# ioam3358 register map
Registers are 32-bit, access not given, no defined reset value unless marked. A register's access mark holds for its fields unless they carry their own. Addresses are absolute; registers are grouped by the start of their names; [hi:lo] are bit positions; {n}, {i} and the like mark numbered series.

## MCSPI1
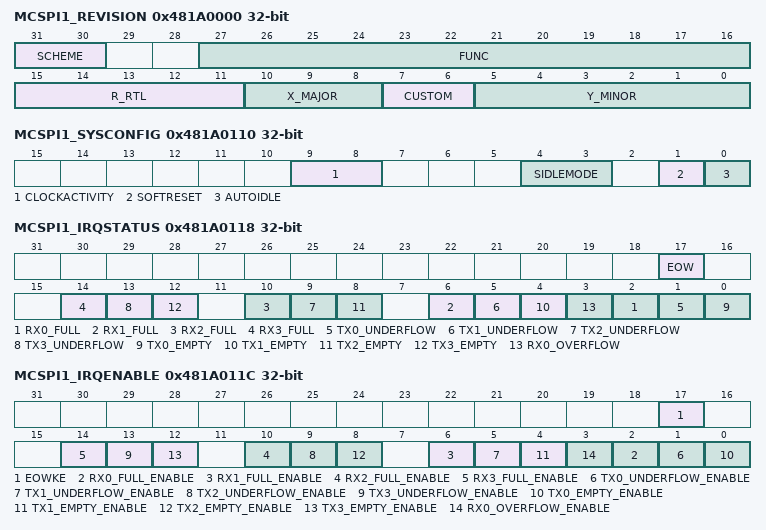
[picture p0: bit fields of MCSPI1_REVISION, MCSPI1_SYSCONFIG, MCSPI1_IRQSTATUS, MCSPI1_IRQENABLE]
0x481A0000 MCSPI1_REVISION
  [31:30] SCHEME, [27:16] FUNC, [15:11] R_RTL, [10:8] X_MAJOR, [7:6] CUSTOM, [5:0] Y_MINOR
0x481A0110 MCSPI1_SYSCONFIG
  [9:8] CLOCKACTIVITY, [4:3] SIDLEMODE, [1] SOFTRESET, [0] AUTOIDLE
0x481A0114 MCSPI1_SYSSTATUS
  [0] RESETDONE
0x481A0118 MCSPI1_IRQSTATUS
  [17] EOW, [4n+2] RX{n}_FULL (n=0..3), [4n+1] TX{n}_UNDERFLOW (n=0..3), [4n] TX{n}_EMPTY (n=0..3), [3] RX0_OVERFLOW
0x481A011C MCSPI1_IRQENABLE
  [17] EOWKE, [4n+2] RX{n}_FULL_ENABLE (n=0..3), [4n+1] TX{n}_UNDERFLOW_ENABLE (n=0..3), [4n] TX{n}_EMPTY_ENABLE (n=0..3), [3] RX0_OVERFLOW_ENABLE
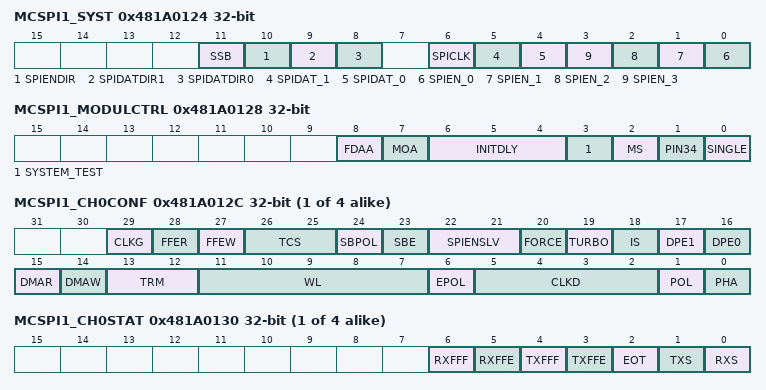
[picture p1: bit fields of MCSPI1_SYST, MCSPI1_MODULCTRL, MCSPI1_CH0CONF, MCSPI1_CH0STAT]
0x481A0124 MCSPI1_SYST
  [11] SSB, [10] SPIENDIR, [9] SPIDATDIR1, [8] SPIDATDIR0, [6] SPICLK, [5] SPIDAT_1, [4] SPIDAT_0, [n] SPIEN_{n} (n=0..3)
0x481A0128 MCSPI1_MODULCTRL
  [8] FDAA, [7] MOA, [6:4] INITDLY, [3] SYSTEM_TEST, [2] MS, [1] PIN34, [0] SINGLE
{0x481A012C+0x14*i} MCSPI1_CH{i}CONF (i=0..3)
  [29] CLKG, [28] FFER, [27] FFEW, [26:25] TCS, [24] SBPOL, [23] SBE, [22:21] SPIENSLV, [20] FORCE, [19] TURBO, [18] IS, [17] DPE1, [16] DPE0, [15] DMAR, [14] DMAW, [13:12] TRM, [11:7] WL, [6] EPOL, [5:2] CLKD, [1] POL, [0] PHA
{0x481A0130+0x14*i} MCSPI1_CH{i}STAT (i=0..3)
  [6] RXFFF, [5] RXFFE, [4] TXFFF, [3] TXFFE, [2] EOT, [1] TXS, [0] RXS
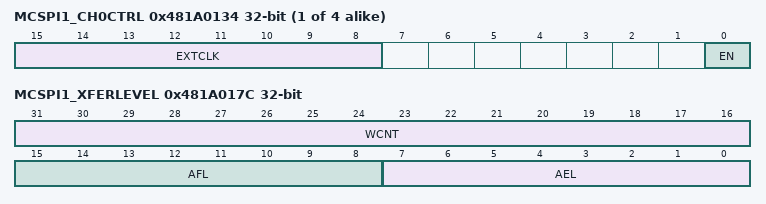
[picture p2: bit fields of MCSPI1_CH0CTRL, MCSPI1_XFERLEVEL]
{0x481A0134+0x14*i} MCSPI1_CH{i}CTRL (i=0..3)
  [15:8] EXTCLK, [0] EN
{0x481A0138+0x14*i} MCSPI1_TX{i} (i=0..3)
{0x481A013C+0x14*i} MCSPI1_RX{i} (i=0..3)
0x481A017C MCSPI1_XFERLEVEL
  [31:16] WCNT, [15:8] AFL, [7:0] AEL
0x481A0180 MCSPI1_DAFTX
0x481A0184 MCSPI1_DAFRX

## GPIO0
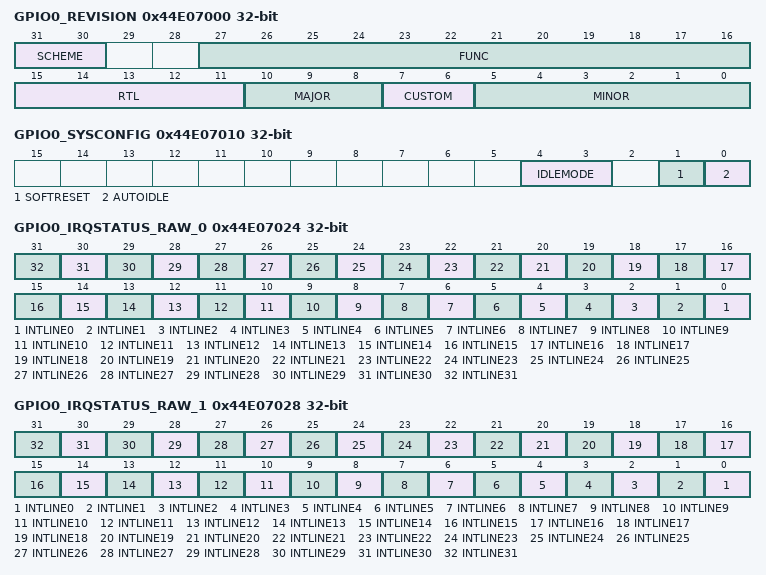
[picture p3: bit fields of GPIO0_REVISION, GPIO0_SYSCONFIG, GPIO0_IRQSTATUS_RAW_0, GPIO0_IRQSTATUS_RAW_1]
0x44E07000 GPIO0_REVISION
  [31:30] SCHEME, [27:16] FUNC, [15:11] RTL, [10:8] MAJOR, [7:6] CUSTOM, [5:0] MINOR
0x44E07010 GPIO0_SYSCONFIG
  [4:3] IDLEMODE, [1] SOFTRESET, [0] AUTOIDLE
0x44E07020 GPIO0_GPIO_EOI
  [0] LINE_NUMBER
0x44E07024 GPIO0_IRQSTATUS_RAW_0
  [n] INTLINE{n} (n=0..31)
0x44E07028 GPIO0_IRQSTATUS_RAW_1
  [n] INTLINE{n} (n=0..31)
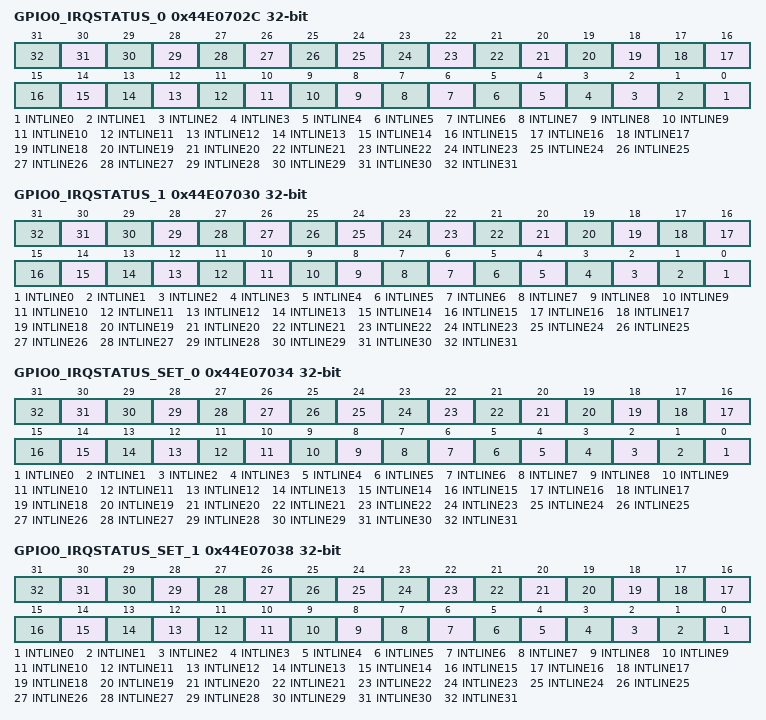
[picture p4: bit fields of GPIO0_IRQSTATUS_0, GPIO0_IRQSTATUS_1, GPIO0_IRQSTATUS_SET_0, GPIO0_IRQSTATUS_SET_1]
0x44E0702C GPIO0_IRQSTATUS_0
  [n] INTLINE{n} (n=0..31)
0x44E07030 GPIO0_IRQSTATUS_1
  [n] INTLINE{n} (n=0..31)
0x44E07034 GPIO0_IRQSTATUS_SET_0
  [n] INTLINE{n} (n=0..31)
0x44E07038 GPIO0_IRQSTATUS_SET_1
  [n] INTLINE{n} (n=0..31)
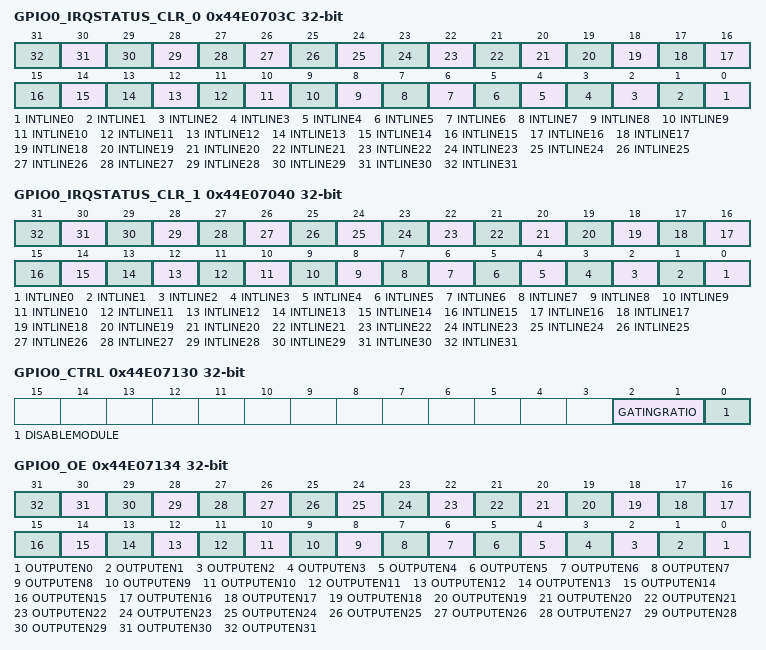
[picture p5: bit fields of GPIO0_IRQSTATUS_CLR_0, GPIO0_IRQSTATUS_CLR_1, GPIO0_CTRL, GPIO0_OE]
0x44E0703C GPIO0_IRQSTATUS_CLR_0
  [n] INTLINE{n} (n=0..31)
0x44E07040 GPIO0_IRQSTATUS_CLR_1
  [n] INTLINE{n} (n=0..31)
0x44E07114 GPIO0_SYSSTATUS
  [0] RESETDONE
0x44E07130 GPIO0_CTRL
  [2:1] GATINGRATIO, [0] DISABLEMODULE
0x44E07134 GPIO0_OE
  [n] OUTPUTEN{n} (n=0..31)
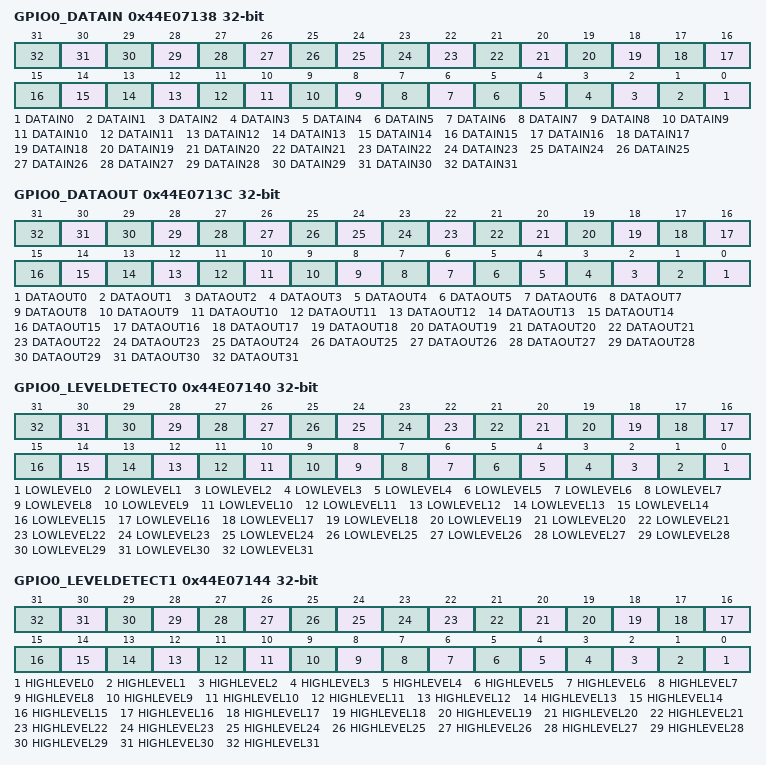
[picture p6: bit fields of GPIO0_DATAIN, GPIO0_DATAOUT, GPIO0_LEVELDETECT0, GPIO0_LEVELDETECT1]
0x44E07138 GPIO0_DATAIN
  [n] DATAIN{n} (n=0..31)
0x44E0713C GPIO0_DATAOUT
  [n] DATAOUT{n} (n=0..31)
0x44E07140 GPIO0_LEVELDETECT0
  [n] LOWLEVEL{n} (n=0..31)
0x44E07144 GPIO0_LEVELDETECT1
  [n] HIGHLEVEL{n} (n=0..31)
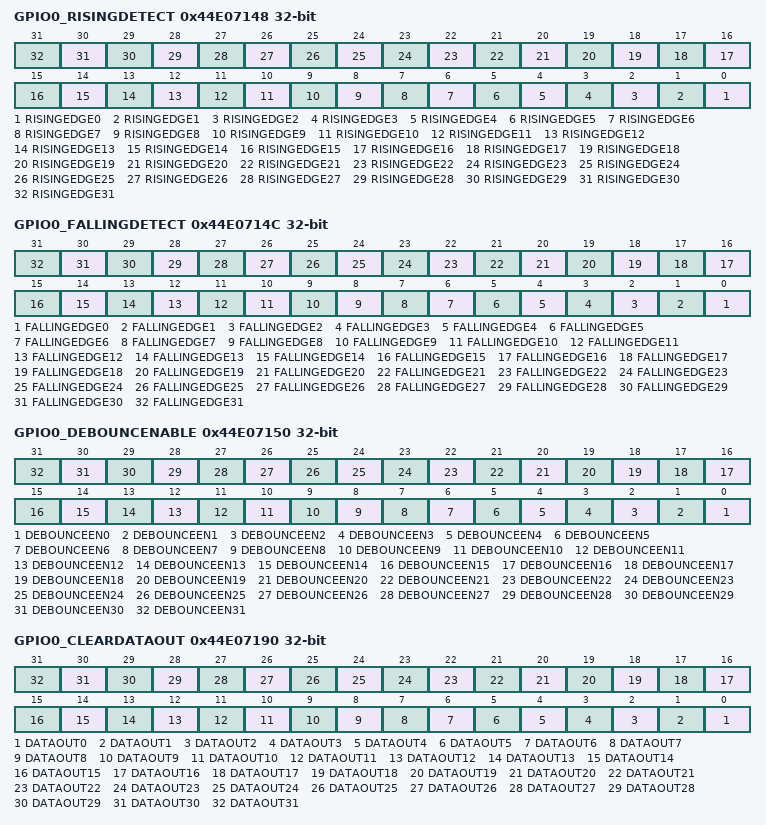
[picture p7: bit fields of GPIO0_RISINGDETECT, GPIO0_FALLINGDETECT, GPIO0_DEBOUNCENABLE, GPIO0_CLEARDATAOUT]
0x44E07148 GPIO0_RISINGDETECT
  [n] RISINGEDGE{n} (n=0..31)
0x44E0714C GPIO0_FALLINGDETECT
  [n] FALLINGEDGE{n} (n=0..31)
0x44E07150 GPIO0_DEBOUNCENABLE
  [n] DEBOUNCEEN{n} (n=0..31)
0x44E07154 GPIO0_DEBOUNCINGTIME
  [7:0] DEBOUNCEVAL
0x44E07190 GPIO0_CLEARDATAOUT
  [n] DATAOUT{n} (n=0..31)
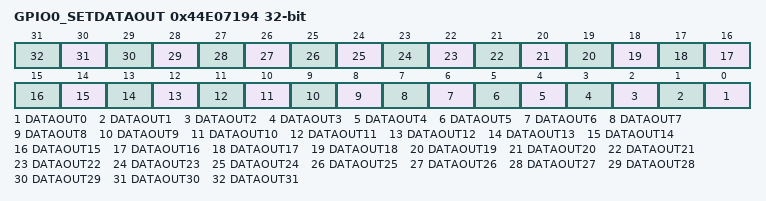
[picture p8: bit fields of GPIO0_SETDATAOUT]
0x44E07194 GPIO0_SETDATAOUT
  [n] DATAOUT{n} (n=0..31)

## GPIO1
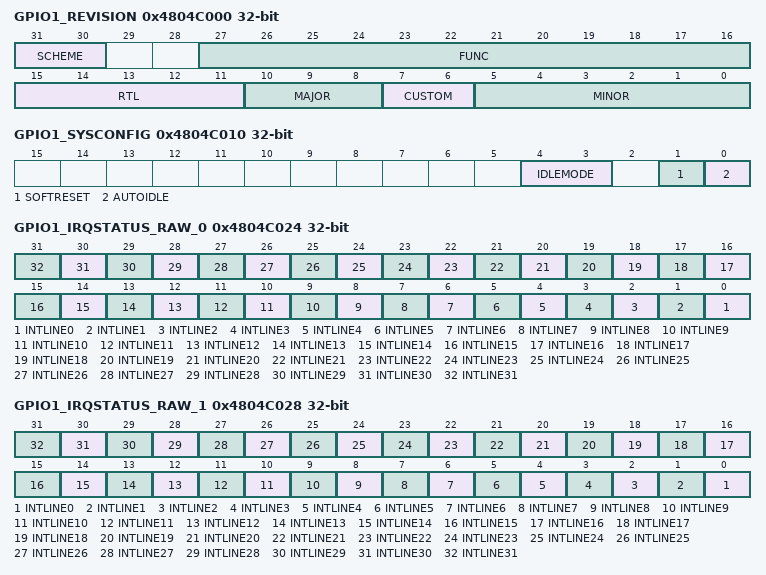
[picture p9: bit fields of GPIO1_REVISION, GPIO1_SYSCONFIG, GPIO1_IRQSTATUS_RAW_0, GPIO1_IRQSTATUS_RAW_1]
0x4804C000 GPIO1_REVISION
  [31:30] SCHEME, [27:16] FUNC, [15:11] RTL, [10:8] MAJOR, [7:6] CUSTOM, [5:0] MINOR
0x4804C010 GPIO1_SYSCONFIG
  [4:3] IDLEMODE, [1] SOFTRESET, [0] AUTOIDLE
0x4804C020 GPIO1_GPIO_EOI
  [0] LINE_NUMBER
0x4804C024 GPIO1_IRQSTATUS_RAW_0
  [n] INTLINE{n} (n=0..31)
0x4804C028 GPIO1_IRQSTATUS_RAW_1
  [n] INTLINE{n} (n=0..31)
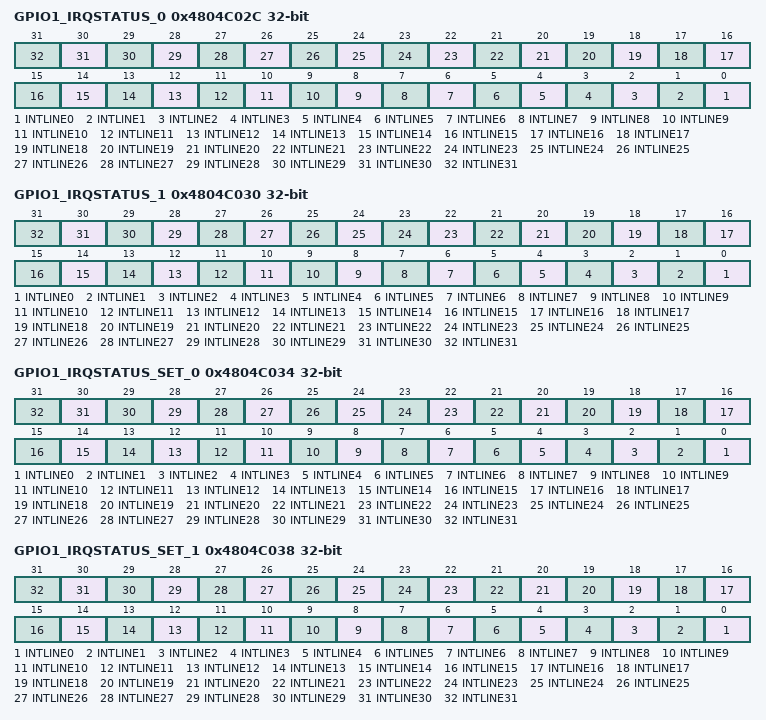
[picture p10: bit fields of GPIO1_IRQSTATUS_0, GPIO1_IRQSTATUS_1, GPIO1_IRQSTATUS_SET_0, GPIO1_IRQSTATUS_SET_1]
0x4804C02C GPIO1_IRQSTATUS_0
  [n] INTLINE{n} (n=0..31)
0x4804C030 GPIO1_IRQSTATUS_1
  [n] INTLINE{n} (n=0..31)
0x4804C034 GPIO1_IRQSTATUS_SET_0
  [n] INTLINE{n} (n=0..31)
0x4804C038 GPIO1_IRQSTATUS_SET_1
  [n] INTLINE{n} (n=0..31)
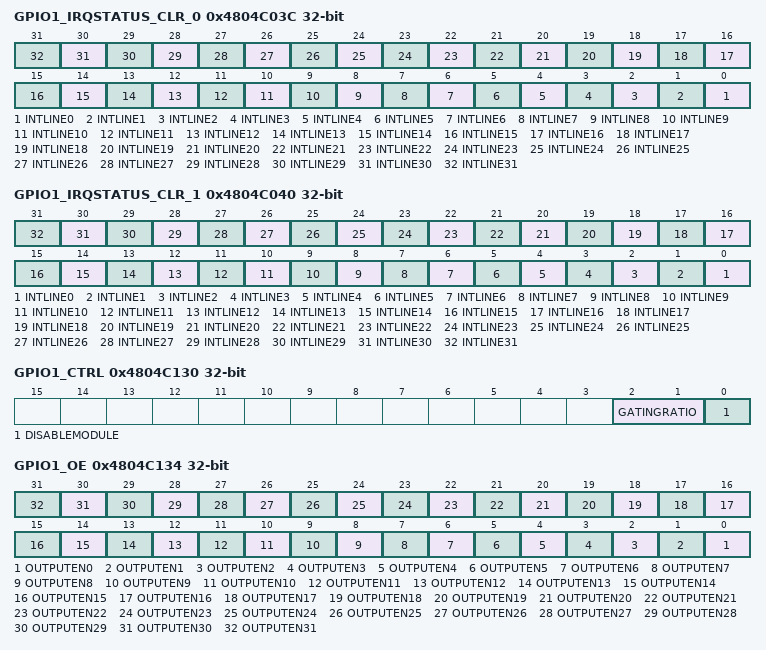
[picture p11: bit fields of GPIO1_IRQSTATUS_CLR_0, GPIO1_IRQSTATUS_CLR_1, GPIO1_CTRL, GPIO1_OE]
0x4804C03C GPIO1_IRQSTATUS_CLR_0
  [n] INTLINE{n} (n=0..31)
0x4804C040 GPIO1_IRQSTATUS_CLR_1
  [n] INTLINE{n} (n=0..31)
0x4804C114 GPIO1_SYSSTATUS
  [0] RESETDONE
0x4804C130 GPIO1_CTRL
  [2:1] GATINGRATIO, [0] DISABLEMODULE
0x4804C134 GPIO1_OE
  [n] OUTPUTEN{n} (n=0..31)
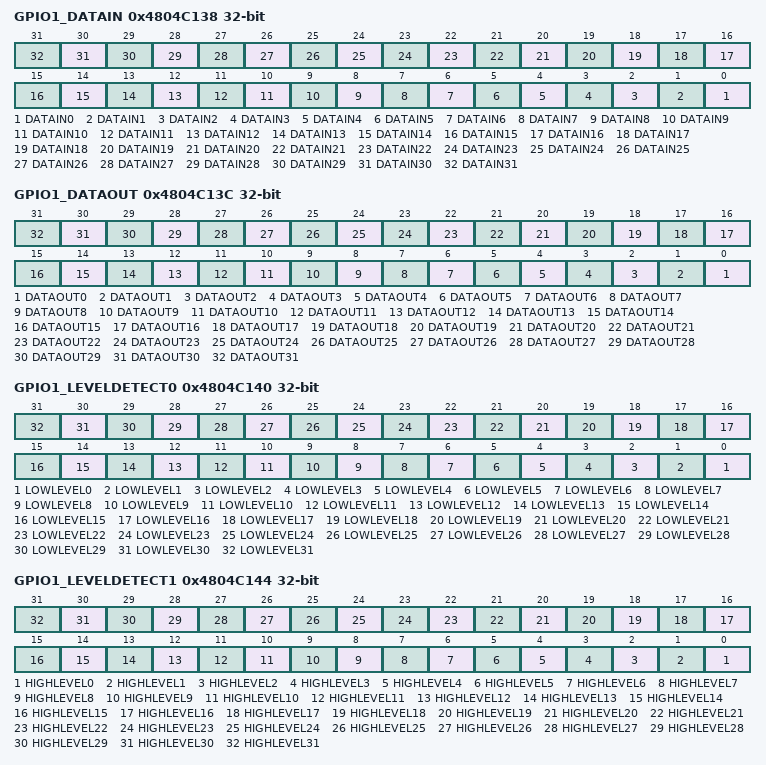
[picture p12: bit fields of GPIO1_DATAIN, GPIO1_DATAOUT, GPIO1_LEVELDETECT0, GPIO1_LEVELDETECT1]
0x4804C138 GPIO1_DATAIN
  [n] DATAIN{n} (n=0..31)
0x4804C13C GPIO1_DATAOUT
  [n] DATAOUT{n} (n=0..31)
0x4804C140 GPIO1_LEVELDETECT0
  [n] LOWLEVEL{n} (n=0..31)
0x4804C144 GPIO1_LEVELDETECT1
  [n] HIGHLEVEL{n} (n=0..31)
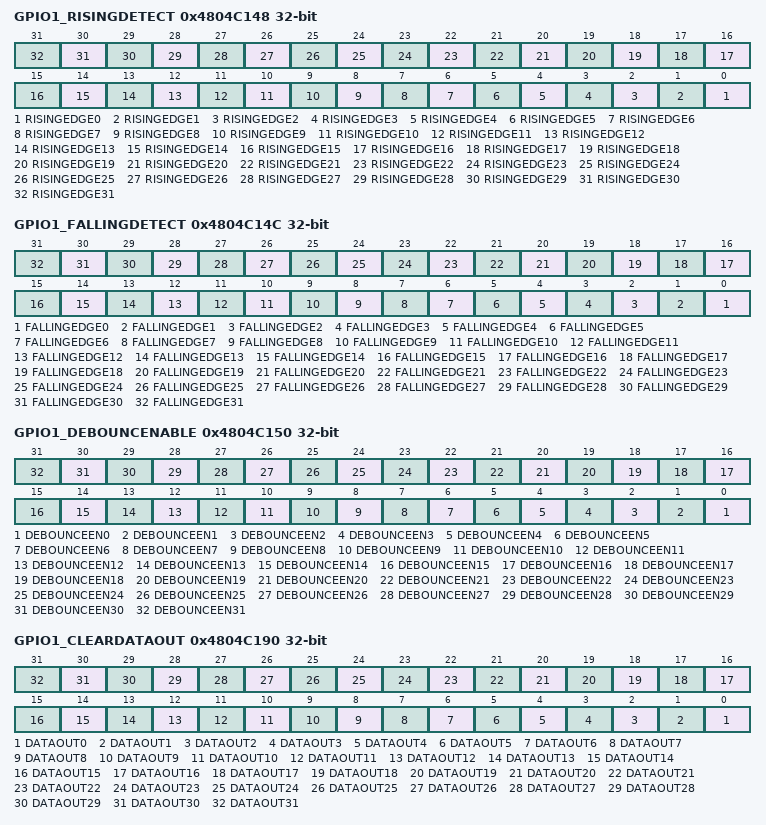
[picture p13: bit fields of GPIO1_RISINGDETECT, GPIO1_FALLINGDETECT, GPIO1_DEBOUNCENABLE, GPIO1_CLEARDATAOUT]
0x4804C148 GPIO1_RISINGDETECT
  [n] RISINGEDGE{n} (n=0..31)
0x4804C14C GPIO1_FALLINGDETECT
  [n] FALLINGEDGE{n} (n=0..31)
0x4804C150 GPIO1_DEBOUNCENABLE
  [n] DEBOUNCEEN{n} (n=0..31)
0x4804C154 GPIO1_DEBOUNCINGTIME
  [7:0] DEBOUNCEVAL
0x4804C190 GPIO1_CLEARDATAOUT
  [n] DATAOUT{n} (n=0..31)
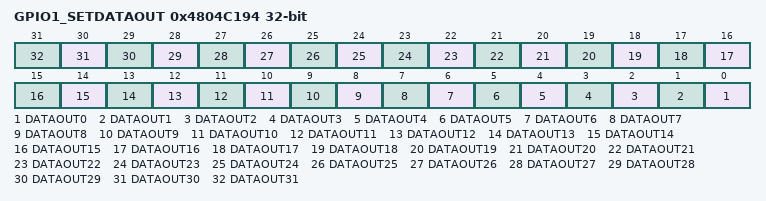
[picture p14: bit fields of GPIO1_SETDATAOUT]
0x4804C194 GPIO1_SETDATAOUT
  [n] DATAOUT{n} (n=0..31)

## GPIO2
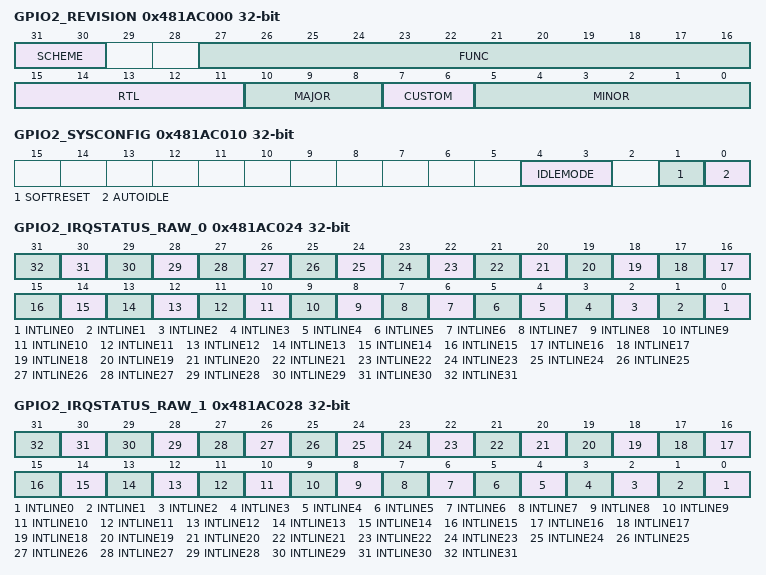
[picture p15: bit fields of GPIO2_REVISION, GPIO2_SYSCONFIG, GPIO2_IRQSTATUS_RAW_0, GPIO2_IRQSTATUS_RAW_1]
0x481AC000 GPIO2_REVISION
  [31:30] SCHEME, [27:16] FUNC, [15:11] RTL, [10:8] MAJOR, [7:6] CUSTOM, [5:0] MINOR
0x481AC010 GPIO2_SYSCONFIG
  [4:3] IDLEMODE, [1] SOFTRESET, [0] AUTOIDLE
0x481AC020 GPIO2_GPIO_EOI
  [0] LINE_NUMBER
0x481AC024 GPIO2_IRQSTATUS_RAW_0
  [n] INTLINE{n} (n=0..31)
0x481AC028 GPIO2_IRQSTATUS_RAW_1
  [n] INTLINE{n} (n=0..31)
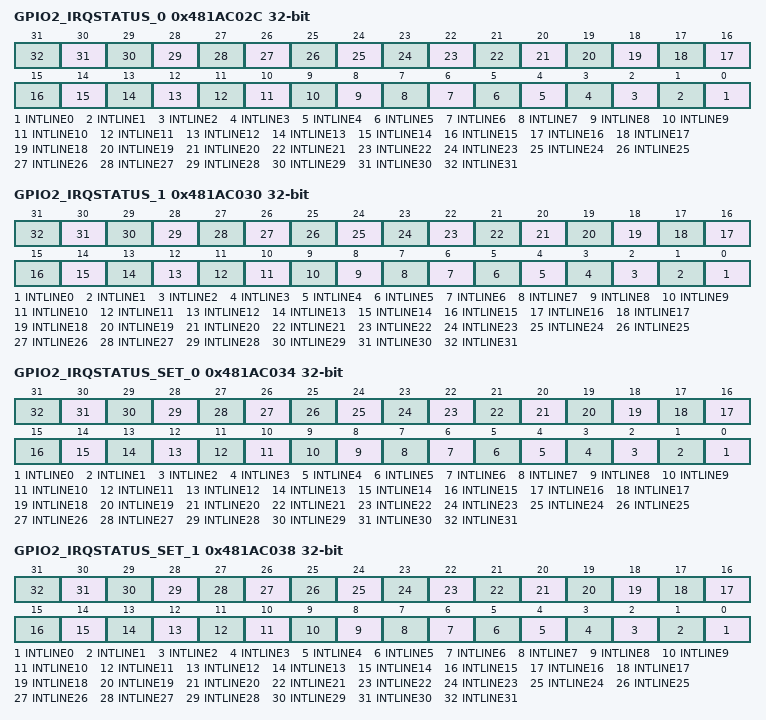
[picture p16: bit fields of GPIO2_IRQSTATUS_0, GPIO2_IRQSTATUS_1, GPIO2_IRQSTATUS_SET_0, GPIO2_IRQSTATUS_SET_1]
0x481AC02C GPIO2_IRQSTATUS_0
  [n] INTLINE{n} (n=0..31)
0x481AC030 GPIO2_IRQSTATUS_1
  [n] INTLINE{n} (n=0..31)
0x481AC034 GPIO2_IRQSTATUS_SET_0
  [n] INTLINE{n} (n=0..31)
0x481AC038 GPIO2_IRQSTATUS_SET_1
  [n] INTLINE{n} (n=0..31)
0x481AC03C GPIO2_IRQSTATUS_CLR_0
  [n] INTLINE{n} (n=0..31)
0x481AC040 GPIO2_IRQSTATUS_CLR_1
  [n] INTLINE{n} (n=0..31)
0x481AC114 GPIO2_SYSSTATUS
  [0] RESETDONE
0x481AC130 GPIO2_CTRL
  [2:1] GATINGRATIO, [0] DISABLEMODULE
0x481AC134 GPIO2_OE
  [n] OUTPUTEN{n} (n=0..31)
0x481AC138 GPIO2_DATAIN
  [n] DATAIN{n} (n=0..31)
0x481AC13C GPIO2_DATAOUT
  [n] DATAOUT{n} (n=0..31)
0x481AC140 GPIO2_LEVELDETECT0
  [n] LOWLEVEL{n} (n=0..31)
0x481AC144 GPIO2_LEVELDETECT1
  [n] HIGHLEVEL{n} (n=0..31)
0x481AC148 GPIO2_RISINGDETECT
  [n] RISINGEDGE{n} (n=0..31)
0x481AC14C GPIO2_FALLINGDETECT
  [n] FALLINGEDGE{n} (n=0..31)
0x481AC150 GPIO2_DEBOUNCENABLE
  [n] DEBOUNCEEN{n} (n=0..31)
0x481AC154 GPIO2_DEBOUNCINGTIME
  [7:0] DEBOUNCEVAL
0x481AC190 GPIO2_CLEARDATAOUT
  [n] DATAOUT{n} (n=0..31)
0x481AC194 GPIO2_SETDATAOUT
  [n] DATAOUT{n} (n=0..31)

## GPIO3
0x481AE000 GPIO3_REVISION
  [31:30] SCHEME, [27:16] FUNC, [15:11] RTL, [10:8] MAJOR, [7:6] CUSTOM, [5:0] MINOR
0x481AE010 GPIO3_SYSCONFIG
  [4:3] IDLEMODE, [1] SOFTRESET, [0] AUTOIDLE
0x481AE020 GPIO3_GPIO_EOI
  [0] LINE_NUMBER
0x481AE024 GPIO3_IRQSTATUS_RAW_0
  [n] INTLINE{n} (n=0..31)
0x481AE028 GPIO3_IRQSTATUS_RAW_1
  [n] INTLINE{n} (n=0..31)
0x481AE02C GPIO3_IRQSTATUS_0
  [n] INTLINE{n} (n=0..31)
0x481AE030 GPIO3_IRQSTATUS_1
  [n] INTLINE{n} (n=0..31)
0x481AE034 GPIO3_IRQSTATUS_SET_0
  [n] INTLINE{n} (n=0..31)
0x481AE038 GPIO3_IRQSTATUS_SET_1
  [n] INTLINE{n} (n=0..31)
0x481AE03C GPIO3_IRQSTATUS_CLR_0
  [n] INTLINE{n} (n=0..31)
0x481AE040 GPIO3_IRQSTATUS_CLR_1
  [n] INTLINE{n} (n=0..31)
0x481AE114 GPIO3_SYSSTATUS
  [0] RESETDONE
0x481AE130 GPIO3_CTRL
  [2:1] GATINGRATIO, [0] DISABLEMODULE
0x481AE134 GPIO3_OE
  [n] OUTPUTEN{n} (n=0..31)
0x481AE138 GPIO3_DATAIN
  [n] DATAIN{n} (n=0..31)
0x481AE13C GPIO3_DATAOUT
  [n] DATAOUT{n} (n=0..31)
0x481AE140 GPIO3_LEVELDETECT0
  [n] LOWLEVEL{n} (n=0..31)
0x481AE144 GPIO3_LEVELDETECT1
  [n] HIGHLEVEL{n} (n=0..31)
0x481AE148 GPIO3_RISINGDETECT
  [n] RISINGEDGE{n} (n=0..31)
0x481AE14C GPIO3_FALLINGDETECT
  [n] FALLINGEDGE{n} (n=0..31)
0x481AE150 GPIO3_DEBOUNCENABLE
  [n] DEBOUNCEEN{n} (n=0..31)
0x481AE154 GPIO3_DEBOUNCINGTIME
  [7:0] DEBOUNCEVAL
0x481AE190 GPIO3_CLEARDATAOUT
  [n] DATAOUT{n} (n=0..31)
0x481AE194 GPIO3_SETDATAOUT
  [n] DATAOUT{n} (n=0..31)
